# STM32H7P5 register map
File version: 2.0.0
CPU: CM7 r1p2, little endian, MPU, FPU, 4 interrupt priority bits
Registers are 32-bit, read-write, reset 0x0 unless marked. A register's access mark holds for its fields unless they carry their own. Offsets are from the block's base; [hi:lo] are bit positions; {n}, {i} and the like mark numbered series; 'fields as' and 'values as' point back to an identical list.

## RAMECC1 — RAMECC register block
Base 0x52009000
Same registers: RAMECC2 0x58027000
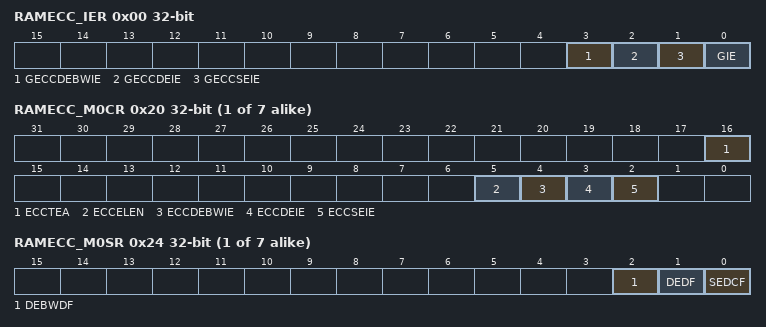
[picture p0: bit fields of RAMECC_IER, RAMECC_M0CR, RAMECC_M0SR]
0x00 RAMECC_IER — RAMECC interrupt enable register
  [3] GECCDEBWIE — Global ECC double error on byte write (BW) interrupt enable
    0=No interrupt generated when an ECC double detection error occurs on byte write; 1=Interrupt generated if an ECC double detection error occurs on byte write
  [2] GECCDEIE — Global ECC double error interrupt enable
    0=No interrupt generated when an ECC double detection error occurs; 1=Interrupt generated if an ECC double detection error occurs
  [1] GECCSEIE — Global ECC single error interrupt enable
    0=No interrupt generated when an ECC single error occurs; 1=Interrupt generated when an ECC single error occurs
  [0] GIE — Global interrupt enable
    0=No interrupt generated when an ECC error occurs; 1=Interrupt generated when an ECC error occurs
{0x20+0x20*i} RAMECC_M{i}CR (i=0..6) — RAMECC monitor {i} configuration register
  [16] ECCTEA — ECC test ECC access
    0=Inactive; 1=Write and read access blocked on ECC memory
  [5] ECCELEN — ECC error latching enable
    0=No error context preserved when an ECC error occurs; 1=Error context preserved when an ECC error occurs
  [4] ECCDEBWIE — ECC double error on byte write (BW) interrupt enable
    values as RAMECC_IER.GECCDEBWIE
  [3] ECCDEIE — ECC double error interrupt enable
    values as RAMECC_IER.GECCDEIE
  [2] ECCSEIE — ECC single error interrupt enable
    values as RAMECC_IER.GECCSEIE
{0x24+0x20*i} RAMECC_M{i}SR (i=0..6) — RAMECC monitor {i} status register
  [2] DEBWDF — ECC double error on byte write (BW) detected flag
    0=No error detected; 1=Error detected
  [1] DEDF — ECC double error detected flag
    0=No error detected; 1=Error detected
  [0] SEDCF — ECC single error detected and corrected flag
    0=No error detected and corrected; 1=Error detected and corrected
{0x28+0x20*i} RAMECC_M{i}FAR ro (i=0..6) — RAMECC monitor {i} failing address register
  [31:0] FADD — ECC error failing address
{0x2C+0x20*i} RAMECC_M{i}FDR ro (i=0..6) — RAMECC monitor {i} failing data register
  [31:0] FDATA — Failing data
{0x34+0x20*i} RAMECC_M{i}FECR ro (i=0..6) — RAMECC monitor {i} failing ECC error code register
  [31:0] FEC — Failing error code

## TIM6 — TIM address block description
Base 0x40001000
Same registers: TIM7 0x40001400
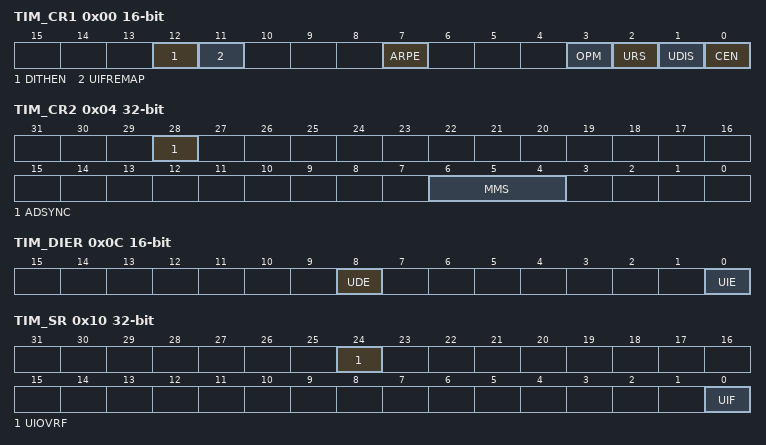
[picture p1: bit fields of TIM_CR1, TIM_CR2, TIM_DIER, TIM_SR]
0x00 TIM_CR1 16-bit — TIM control register 1
  [12] DITHEN — Dithering enable
    0=Dithering disabled; 1=Dithering enabled
  [11] UIFREMAP — UIF status bit remapping
    0=No remapping. UIF status bit is not copied to TIMx_CNT register bit 31.; 1=Remapping enabled. UIF status bit is copied to TIMx_CNT register bit 31.
  [7] ARPE — Auto-reload preload enable
    0=TIMx_ARR register is not buffered; 1=TIMx_ARR register is buffered
  [3] OPM — One-pulse mode
    0=Counter is not stopped at update event; 1=Counter stops counting at the next update event (clearing the CEN bit)
  [2] URS — Update request source
    0=Any of the following events generates an update interrupt or DMA request if enabled. These events can be:; 1=Only counter overflow/underflow generates an update interrupt or DMA request if enabled
  [1] UDIS — Update disable
    0=UEV enabled. The Update (UEV) event is generated by one of the following events:; 1=UEV disabled. The Update event is not generated, shadow registers keep their value (ARR, PSC). However the counter and the prescaler are reinitialized if the UG bit is set or if a hardware reset is received from the slave mode controller.
  [0] CEN — Counter enable
    0=Counter disabled; 1=Counter enabled
0x04 TIM_CR2 — TIM control register 2
  [28] ADSYNC — ADC synchronization
    0=The timer operates independently from the ADC; 1=The timer operation is synchronized with the ADC clock to provide jitter-free sampling point. This mode can be enabled only with specific ADC / timer clock relationship. Refer to Section2.3.8 for requirements.
  [6:4] MMS — Master mode selection
    0=Reset - the UG bit from the TIMx_EGR register is used as a trigger output (tim_trgo); 1=Enable - the Counter enable signal, tim_cnt_en, is used as a trigger output (tim_trgo). It is useful to start several timers at the same time or to control a window in which a slave timer is enabled. The Counter Enable signal is generated when the CEN control bit is written.; 2=Update - The update event is selected as a trigger output (tim_trgo). For instance a master timer can then be used as a prescaler for a slave timer.
0x0C TIM_DIER 16-bit — TIM DMA/Interrupt enable register
  [8] UDE — Update DMA request enable
    0=Update DMA request disabled; 1=Update DMA request enabled
  [0] UIE — Update interrupt enable
    0=Update interrupt disabled; 1=Update interrupt enabled
0x10 TIM_SR — TIM status register
  [24] UIOVRF — Update Interrupt Overrun flag
    0=No Update Interrupt Overrun; 1=Update Interrupt Overrun
  [0] UIF — Update interrupt flag
    0=No update occurred; 1=Update interrupt pending. This bit is set by hardware when the registers are updated:
0x14 TIM_EGR 16-bit wo — TIM event generation register
  [0] UG — Update generation
    0=No action; 1=Re-initializes the timer counter and generates an update of the registers. Note that the prescaler counter is cleared too (but the prescaler ratio is not affected).
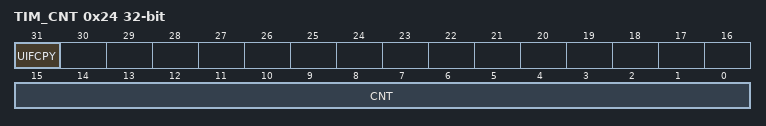
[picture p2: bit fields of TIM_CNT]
0x24 TIM_CNT — TIM counter
  [31] UIFCPY ro — UIF copy
  [15:0] CNT — Counter value
0x28 TIM_PSC 16-bit — TIM prescaler
  [15:0] PSC — Prescaler value
0x2C TIM_ARR reset 0xFFFF — TIM autoreload register
  [19:0] ARR — Auto-reload value

## VREFBUF — VREFBUF register block
Base 0x58003C00
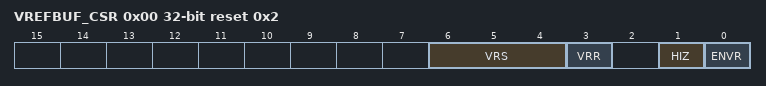
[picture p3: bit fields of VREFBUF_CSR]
0x00 VREFBUF_CSR reset 0x2 — VREFBUF control and status register
  [6:4] VRS — Voltage reference scale
  [3] VRR ro — Voltage reference buffer ready
    0=the voltage reference buffer output is not ready; 1=the voltage reference buffer output reached the requested level
  [1] HIZ — High impedance mode
    0=Vless thansub>REF+less than/sub> pin is internally connected to the voltage reference buffer output; 1=Vless thansub>REF+less than/sub> pin is high impedance
  [0] ENVR — Voltage reference buffer mode enable
    0=Internal voltage reference mode disable (external voltage reference mode); 1=Internal voltage reference mode (reference buffer enable or hold mode) enable
0x04 VREFBUF_CCR (reset mask 0xFFFFFF00) — VREFBUF calibration control register
  [5:0] TRIM — Trimming code

## WWDG — WWDG register block
Base 0x40002C00
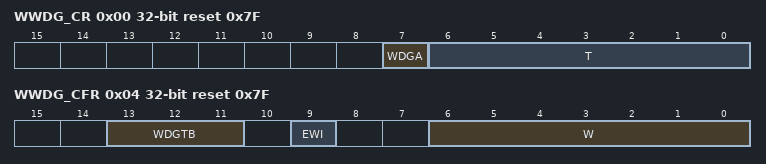
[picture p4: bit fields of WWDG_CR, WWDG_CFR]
0x00 WWDG_CR reset 0x7F — WWDG control register
  [7] WDGA — Activation bit
    0=Watchdog disabled; 1=Watchdog enabled
  [6:0] T — 7-bit counter (MSB to LSB)
0x04 WWDG_CFR reset 0x7F — WWDG configuration register
  [13:11] WDGTB — Timer base
    0=CK counter clock (PCLK div 4096) div 1; 1=CK counter clock (PCLK div 4096) div 2; 2=CK counter clock (PCLK div 4096) div 4; 3=CK counter clock (PCLK div 4096) div 8; 4=CK counter clock (PCLK div 4096) div 16; 5=CK counter clock (PCLK div 4096) div 32; 6=CK counter clock (PCLK div 4096) div 64; 7=CK counter clock (PCLK div 4096) div 128
  [9] EWI — Early wake-up interrupt enable
  [6:0] W — 7-bit window value
0x08 WWDG_SR — WWDG status register
  [0] EWIF — Early wake-up interrupt flag
